# BL602 register map
Vendor: bouffalolab; Series: WiFi BT
high-performance, 32-bit RV32IMAFC core
Registers are 32-bit, read-write, reset 0x0 unless marked. A register's access mark holds for its fields unless they carry their own. Offsets are from the block's base; lines under a group give offsets from that group; [hi:lo] are bit positions; {n}, {i} and the like mark numbered series; 'fields as' and 'values as' point back to an identical list; <NAME> marks a mode.

## Memory map
0x40000000 GLB size 0x1000 — Global register
0x40001000 RF size 0x1000 — RF control
0x40002000 GPIP size 0x1000 — Universal DAC/ADC/ACOMP interface control
0x40003000 SEC_DBG size 0x1000
0x40004000 SEC_ENG size 0x1000
0x40005000 TZC_SEC size 0x1000
0x40006000 TZC_NSEC size 0x1000
0x40007000 EF_DATA_0 size 0x80
0x40007080 EF_DATA_1 size 0x64
0x40007800 EF_CTRL size 0x218 — eFuse memory control
0x40008000 CCI size 0x1000
0x40009000 L1C size 0x1000 — Cache control
0x4000A000 UART size 0x90 — UART control
0x4000A200 SPI size 0x90 — SPI master / slave control
0x4000A300 I2C size 0x100 — I2C control
0x4000A400 PWM size 0xB8 — Pulse width modulation control
0x4000A500 TIMER size 0xC0 — Timer control
0x4000A600 IR size 0xC8 — Infrared remote control
0x4000A700 CKS size 0x10 — Checksum engine
0x4000B000 SF_CTRL size 0x1000 — Flash control
0x4000C000 DMA size 0x1000 — DMA control
0x4000E000 PDS size 0x1000 — Sleep control (power-down sleep)
0x4000F000 HBN size 0x1000 — Deep Sleep Control (Hibernation)
0x40010000 AON size 0x144 — Always-ON periherals

## GPIP — Universal DAC/ADC/ACOMP interface control
Base 0x40002000
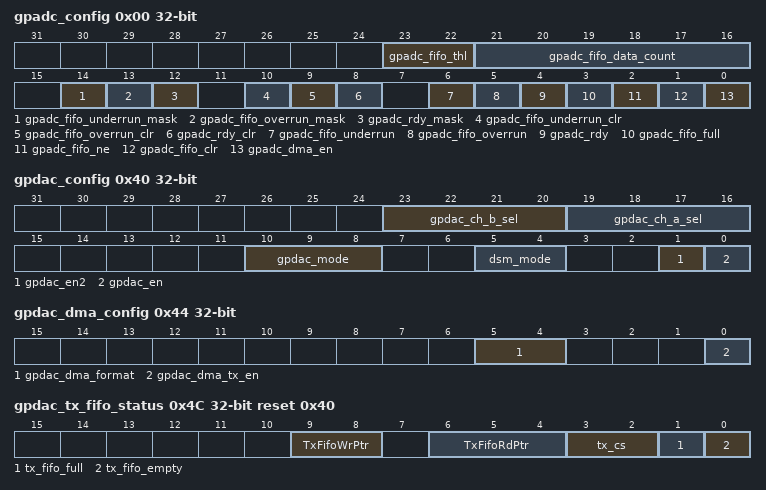
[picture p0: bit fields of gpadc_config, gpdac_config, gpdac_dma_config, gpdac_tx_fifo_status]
0x00 gpadc_config
  [23:22] gpadc_fifo_thl, [21:16] gpadc_fifo_data_count ro, [14] gpadc_fifo_underrun_mask, [13] gpadc_fifo_overrun_mask, [12] gpadc_rdy_mask, [10] gpadc_fifo_underrun_clr, [9] gpadc_fifo_overrun_clr, [8] gpadc_rdy_clr, [6] gpadc_fifo_underrun ro, [5] gpadc_fifo_overrun ro, [4] gpadc_rdy ro, [3] gpadc_fifo_full ro, [2] gpadc_fifo_ne ro, [1] gpadc_fifo_clr, [0] gpadc_dma_en
0x04 gpadc_dma_rdata ro
  [25:0] gpadc_dma_rdata
0x40 gpdac_config
  [23:20] gpdac_ch_b_sel, [19:16] gpdac_ch_a_sel, [10:8] gpdac_mode, [5:4] dsm_mode, [1] gpdac_en2, [0] gpdac_en
0x44 gpdac_dma_config
  [5:4] gpdac_dma_format, [0] gpdac_dma_tx_en
0x48 gpdac_dma_wdata wo
0x4C gpdac_tx_fifo_status ro reset 0x40
  [9:8] TxFifoWrPtr, [6:4] TxFifoRdPtr, [3:2] tx_cs, [1] tx_fifo_full, [0] tx_fifo_empty

## SEC_DBG
Base 0x40003000
0x00 sd_chip_id_low ro
0x04 sd_chip_id_high ro
0x08 sd_wifi_mac_low ro
0x0C sd_wifi_mac_high ro
0x10 sd_dbg_pwd_low
0x14 sd_dbg_pwd_high
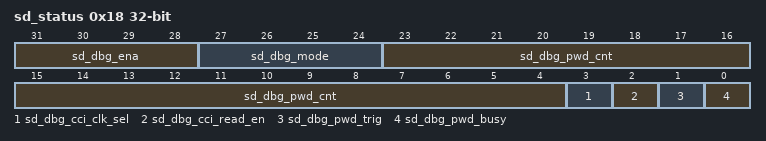
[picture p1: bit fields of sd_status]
0x18 sd_status
  [31:28] sd_dbg_ena ro, [27:24] sd_dbg_mode ro, [23:4] sd_dbg_pwd_cnt ro, [3] sd_dbg_cci_clk_sel, [2] sd_dbg_cci_read_en, [1] sd_dbg_pwd_trig, [0] sd_dbg_pwd_busy ro
0x1C sd_dbg_reserved

## TZC_SEC
Base 0x40005000
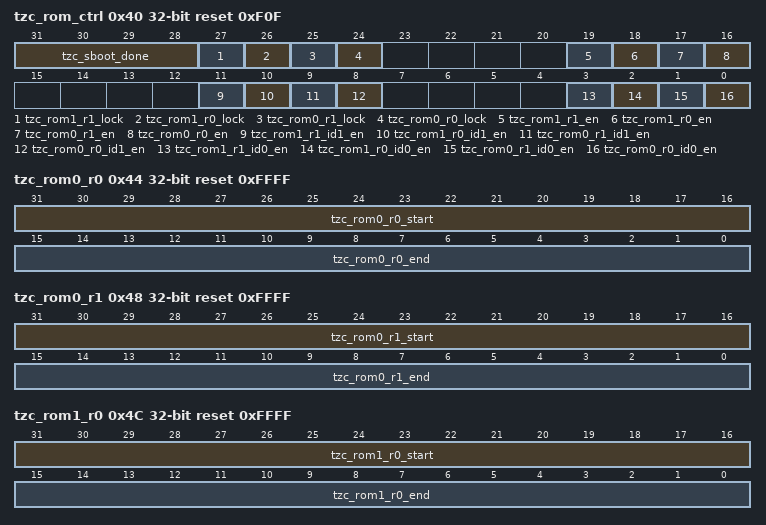
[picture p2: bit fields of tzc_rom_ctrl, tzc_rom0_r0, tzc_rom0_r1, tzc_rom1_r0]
0x40 tzc_rom_ctrl reset 0xF0F
  [31:28] tzc_sboot_done, [27] tzc_rom1_r1_lock, [26] tzc_rom1_r0_lock, [25] tzc_rom0_r1_lock, [24] tzc_rom0_r0_lock, [19] tzc_rom1_r1_en, [18] tzc_rom1_r0_en, [17] tzc_rom0_r1_en, [16] tzc_rom0_r0_en, [11] tzc_rom1_r1_id1_en, [10] tzc_rom1_r0_id1_en, [9] tzc_rom0_r1_id1_en, [8] tzc_rom0_r0_id1_en, [3] tzc_rom1_r1_id0_en, [2] tzc_rom1_r0_id0_en, [1] tzc_rom0_r1_id0_en, [0] tzc_rom0_r0_id0_en
0x44 tzc_rom0_r0 reset 0xFFFF
  [31:16] tzc_rom0_r0_start, [15:0] tzc_rom0_r0_end
0x48 tzc_rom0_r1 reset 0xFFFF
  [31:16] tzc_rom0_r1_start, [15:0] tzc_rom0_r1_end
0x4C tzc_rom1_r0 reset 0xFFFF
  [31:16] tzc_rom1_r0_start, [15:0] tzc_rom1_r0_end
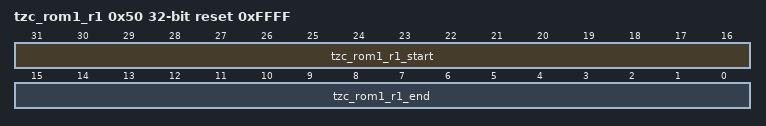
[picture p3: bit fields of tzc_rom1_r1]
0x50 tzc_rom1_r1 reset 0xFFFF
  [31:16] tzc_rom1_r1_start, [15:0] tzc_rom1_r1_end

## TZC_NSEC
Base 0x40006000
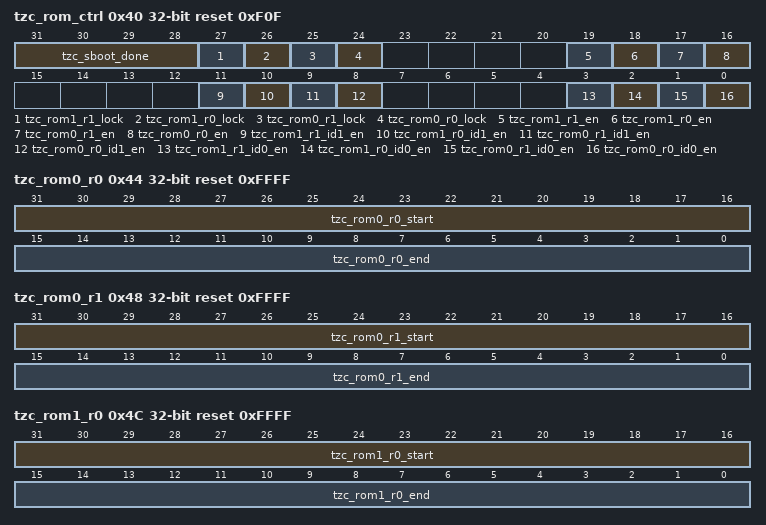
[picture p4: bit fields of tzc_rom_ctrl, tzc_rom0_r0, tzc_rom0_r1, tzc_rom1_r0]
0x40 tzc_rom_ctrl ro reset 0xF0F
  [31:28] tzc_sboot_done, [27] tzc_rom1_r1_lock, [26] tzc_rom1_r0_lock, [25] tzc_rom0_r1_lock, [24] tzc_rom0_r0_lock, [19] tzc_rom1_r1_en, [18] tzc_rom1_r0_en, [17] tzc_rom0_r1_en, [16] tzc_rom0_r0_en, [11] tzc_rom1_r1_id1_en, [10] tzc_rom1_r0_id1_en, [9] tzc_rom0_r1_id1_en, [8] tzc_rom0_r0_id1_en, [3] tzc_rom1_r1_id0_en, [2] tzc_rom1_r0_id0_en, [1] tzc_rom0_r1_id0_en, [0] tzc_rom0_r0_id0_en
0x44 tzc_rom0_r0 ro reset 0xFFFF
  [31:16] tzc_rom0_r0_start, [15:0] tzc_rom0_r0_end
0x48 tzc_rom0_r1 ro reset 0xFFFF
  [31:16] tzc_rom0_r1_start, [15:0] tzc_rom0_r1_end
0x4C tzc_rom1_r0 ro reset 0xFFFF
  [31:16] tzc_rom1_r0_start, [15:0] tzc_rom1_r0_end
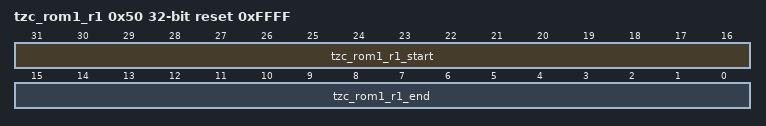
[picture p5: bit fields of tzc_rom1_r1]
0x50 tzc_rom1_r1 ro reset 0xFFFF
  [31:16] tzc_rom1_r1_start, [15:0] tzc_rom1_r1_end
